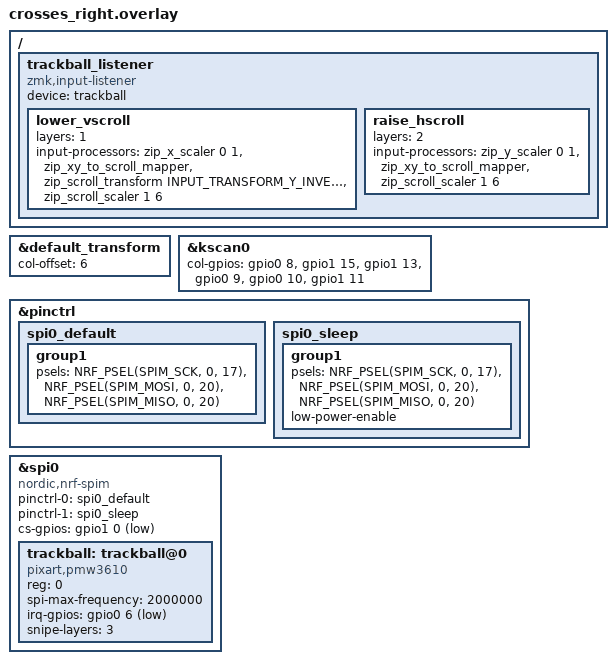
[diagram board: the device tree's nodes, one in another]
/*
 * Copyright (c) 2020 ZMK Contributors
 *
 * SPDX-License-Identifier: MIT
 */
 
#include "crosses.dtsi"
#include <input/processors.dtsi>
#include <dt-bindings/zmk/input_transform.h>

&default_transform {
    col-offset = <6>;
}; 

&kscan0 {
	col-gpios
		= <&gpio0 8 (GPIO_ACTIVE_HIGH | GPIO_PULL_DOWN)>
		, <&gpio1 15 (GPIO_ACTIVE_HIGH | GPIO_PULL_DOWN)>
		, <&gpio1 13 (GPIO_ACTIVE_HIGH | GPIO_PULL_DOWN)>
		, <&gpio0 9 (GPIO_ACTIVE_HIGH | GPIO_PULL_DOWN)>
		, <&gpio0 10  (GPIO_ACTIVE_HIGH | GPIO_PULL_DOWN)>
		, <&gpio1 11 (GPIO_ACTIVE_HIGH | GPIO_PULL_DOWN)>
		
		;
};


// trackball bus
&pinctrl {
    spi0_default: spi0_default {
        group1 {
            psels = <NRF_PSEL(SPIM_SCK, 0, 17)>,
                <NRF_PSEL(SPIM_MOSI, 0, 20)>,
                <NRF_PSEL(SPIM_MISO, 0, 20)>;
        };
    };

    spi0_sleep: spi0_sleep {
        group1 {
            psels = <NRF_PSEL(SPIM_SCK, 0, 17)>,
                <NRF_PSEL(SPIM_MOSI, 0, 20)>,
                <NRF_PSEL(SPIM_MISO, 0, 20)>;
            low-power-enable;
        };
    };
};

&spi0 {
    status = "okay";
    compatible = "nordic,nrf-spim";
    pinctrl-0 = <&spi0_default>;
    pinctrl-1 = <&spi0_sleep>;
    pinctrl-names = "default", "sleep";
    cs-gpios = <&gpio1 0 GPIO_ACTIVE_LOW>;

    trackball: trackball@0 {
        status = "okay";
        compatible = "pixart,pmw3610";
        reg = <0>;
        spi-max-frequency = <2000000>;
        irq-gpios = <&gpio0 6 (GPIO_ACTIVE_LOW | GPIO_PULL_UP)>;
        //scroll-layers = <4>;
        snipe-layers = <3>;
        // automouse-layer = <3>;
    };
};





/ {
    trackball_listener {
        compatible = "zmk,input-listener";
        device = <&trackball>;

        /* Lower (layer 1): vertical-only scroll. Zero X, map Y->WHEEL, invert to match the
         * driver's native scroll direction, then ~ driver speed (tick 24 / CPI divisor 4). */
        lower_vscroll {
            layers = <1>;
            input-processors = <&zip_x_scaler 0 1>,
                               <&zip_xy_to_scroll_mapper>,
                               <&zip_scroll_transform INPUT_TRANSFORM_Y_INVERT>,
                               <&zip_scroll_scaler 1 6>;
        };

        /* Raise (layer 2): horizontal-only scroll. Zero Y, map X->HWHEEL. */
        raise_hscroll {
            layers = <2>;
            input-processors = <&zip_y_scaler 0 1>,
                               <&zip_xy_to_scroll_mapper>,
                               <&zip_scroll_scaler 1 6>;
        };
    };
};


